# RA register map
Vendor: Renesas; Series: All Chips; File version: x.xx
Registers are 32-bit, read-write, reset 0x0 unless marked. A register's access mark holds for its fields unless they carry their own. Offsets are from the block's base; [hi:lo] are bit positions; lines under a group give offsets from that group; {n}, {i} and the like mark numbered series; 'fields as' and 'values as' point back to an identical list.

## R_ETHERC_EPTPC — Ethernet PTP Controller
Base 0x40065800
Same registers: R_ETHERC_EPTPC1 0x40065C00
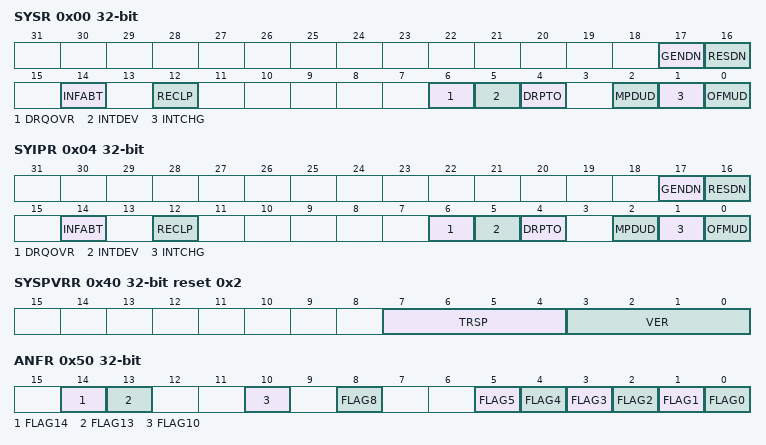
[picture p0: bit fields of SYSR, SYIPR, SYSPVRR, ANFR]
0x00 SYSR — SYNFP Status Register
  [17] GENDN write-1-clears read-modifies — Generation Stop Completion Detection Flag
    0=Stopping generation has not been completed; 1=Stopping generation has been completed
  [16] RESDN write-1-clears read-modifies — Response Stop Completion Detection Flag
    0=Stopping responses has not been completed; 1=Stopping responses has been completed
  [14] INFABT write-1-clears read-modifies — Control Information Abnormality Detection Flag
    0=No abnormality in control information; 1=Abnormality in control information
  [12] RECLP write-1-clears read-modifies — Loop Reception Detection Flag
    0=A received message has not returned through a loop; 1=A received message has returned through a loop
  [6] DRQOVR write-1-clears read-modifies — Delay_Req Reception FIFO Overflow Detection Flag
    0=The received Delay_Req has not caused the reception FIFO to overflow; 1=The received Delay_Req has caused the reception FIFO to overflow
  [5] INTDEV write-1-clears read-modifies — Receive logMessageInterval Value Out-of-Range Flag
    0=The received logMessageInterval value is within the range; 1=The received logMessageInterval value is out of the range
  [4] DRPTO write-1-clears read-modifies — Delay_Resp/Pdelay_Resp Reception Timeout Detection Flag
    0=A Delay_Resp/Pdelay_Resp timeout has not occurred; 1=A Delay_Resp/Pdelay_Resp timeout has occurred
  [2] MPDUD write-1-clears read-modifies — meanPathDelay Value Update Flag
    0=The meanPathDelay value has not been updated; 1=The meanPathDelay value has been updated
  [1] INTCHG write-1-clears read-modifies — Receive logMessageInterval Value Change Detection Flag
    0=No change in the received logMessageInterval value; 1=A change in the received logMessageInterval value
  [0] OFMUD write-1-clears read-modifies — offsetFromMaster Value Update Flag
    0=The offsetFromMaster value has not been updated; 1=The offsetFromMaster value has been updated
0x04 SYIPR — SYNFP Status Notification Permission Register
  [17] GENDN — SYSR.GENDN Status Notification Permission
    0=Prohibits notification of the state of SYSR.GENDN; 1=Permits notification of the state of SYSR.GENDN
  [16] RESDN — SYSR.RESDN Status Notification Permission
    0=Prohibits notification of the state of SYSR.RESDN; 1=Permits notification of the state of SYSR.RESDN
  [14] INFABT — SYSR.INFABT Status Notification Permission
    0=Prohibits notification of the state of SYSR.INFABT; 1=Permits notification of the state of SYSR.INFABT
  [12] RECLP — SYSR.RECLP Status Notification Permission
    0=Prohibits notification of the state of SYSR.RECLP; 1=Permits notification of the state of SYSR.RECLP
  [6] DRQOVR — SYSR.DRQOVR Status Notification Permission
    0=Prohibits notification of the state of SYSR.DRQOVR; 1=Permits notification of the state of SYSR.DRQOVR
  [5] INTDEV — SYSR.INTDEV Status Notification Permission
    0=Prohibits notification of the state of SYSR.INTDEV; 1=Permits notification of the state of SYSR.INTDEV
  [4] DRPTO — SYSR.DRPTO Status Notification Permission
    0=Prohibits notification of the state of SYSR.DRPTO; 1=Permits notification of the state of SYSR.DRPTO
  [2] MPDUD — SYSR.MPDUD Status Notification Permission
    0=Prohibits notification of the state of SYSR.MPDUD; 1=Permits notification of the state of SYSR.MPDUD
  [1] INTCHG — SYSR.INTCHG Status Notification Permission
    0=Prohibits notification of the state of SYSR.INTCHG; 1=Permits notification of the state of SYSR.INTCHG
  [0] OFMUD — SYSR.OFMUD Status Notification Permission
    0=Prohibits notification of the state of SYSR.OFMUD; 1=Permits notification of the state of SYSR.OFMUD
0x10 SYMACRU — SYNFP MAC Address Registers
  [23:0] SYMACRU — These bits hold the setting for the higher-order 24 bits of the local MAC address.
0x14 SYMACRL — SYNFP MAC Address Registers
  [23:0] SYMACRL — These bits hold the setting for the lower-order 24 bits of the local MAC address.
0x18 SYLLCCTLR reset 0x3 — SYNFP LLC-CTL Value Register
  [7:0] CTL — LLC-CTL FieldThese bits specify the value used for the control field in the LLC sublayer when generating IEEE802.3 frames.
0x1C SYIPADDRR — SYNFP Local IP Address Register
  [31:0] SYIPADDRR — These bits hold the setting for the local IP address.
0x40 SYSPVRR reset 0x2 — SYNFP Specification Version Setting Register
  [7:4] TRSP — transportSpecific Field ValueThese bits are used to set the transportSpecific field value of the PTP v2 header.When a message is received, this value is compared with the transportSpecific field of the received frame.In generating messages, the value is used for the transportSpecific field of the frame for transmission.Set these bits to 0000b (IEEE 1588).
  [3:0] VER — versionPTP Field ValueThese bits are used to set the versionPTP field value of the PTP v2 header.When a message is received, this value is compared with the versionPTP field of the received frame.In generating messages, the value is used for the versionPTP field of the frame for transmission.Set these bits to 0010b (PTP v2).
0x44 SYDOMR — SYNFP Domain Number Setting Register
  [7:0] DNUM — domainNumber Field Value SettingThese bits are used to set the domainNumber field value of the PTP v2 header.When a message is received, this value is compared with the domainNumber field of the received frame as a condition for PTP reception processing.In generating messages, the value is used for the domainNumber field of the frame for transmission.
0x50 ANFR — Announce Message Flag Field Setting Register
  [14] FLAG14 — PTP profile Specific 2
    0=PTP profile Specific 2 is set to FALSE; 1=PTP profile Specific 2 is set to TRUE
  [13] FLAG13 — PTP profile Specific 1
    0=PTP profile Specific 1 is set to FALSE; 1=PTP profile Specific 1 is set to TRUE
  [10] FLAG10 — unicastFlag
    0=unicastFlag is set to FALSE; 1=unicastFlag is set to TRUE
  [8] FLAG8 — alternateMasterFlag
    0=alternateMasterFlag is set to FALSE; 1=alternateMasterFlag is set to TRUE
  [5] FLAG5 — frequencyTraceableThis bit is used to set the logical value of the frequencyTraceable member of timePropertiesDS.
    0=frequencyTraceable is set to FALSE; 1=frequencyTraceable is set to TRUE
  [4] FLAG4 — timeTraceableThis bit is used to set the logical value of the timeTraceable member of timePropertiesDS.
    0=timeTraceable is set to FALSE; 1=timeTraceable is set to TRUE
  [3] FLAG3 — ptpTimescaleThis bit is used to set the logical value of the ptpTimescale member of timePropertiesDS.
    0=ptpTimescale is set to FALSE; 1=ptpTimescale is set to TRUE
  [2] FLAG2 — currentUtcOffsetValidThis bit is used to set the logical value of the currentUtcOffsetValid member of timePropertiesDS.
    0=currentUtcOffsetValid is set to FALSE; 1=currentUtcOffsetValid is set to TRUE
  [1] FLAG1 — leap59This bit is used to set the logical value of the leap59 member of timePropertiesDS.
    0=leap59 is set to FALSE; 1=leap59 is set to TRUE
  [0] FLAG0 — leap61This bit is used to set the logical value of the leap61 member of timePropertiesDS.
    0=leap61 is set to FALSE; 1=leap61 is set to TRUE
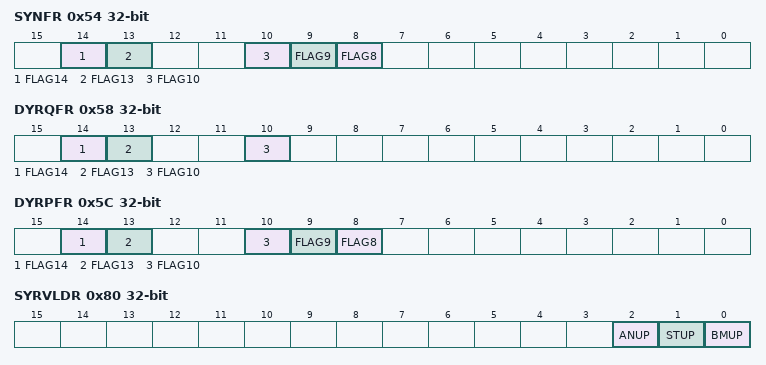
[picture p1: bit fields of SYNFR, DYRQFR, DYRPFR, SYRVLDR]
0x54 SYNFR — Sync Message Flag Field Setting Register
  [14] FLAG14 — PTP profile Specific 2
    values as ANFR.FLAG14
  [13] FLAG13 — PTP profile Specific 1
    values as ANFR.FLAG13
  [10] FLAG10 — unicastFlag
    0=unicastFlag is set to FALSE; 1=unicastFlag is set to TRUE
  [9] FLAG9 — twoStepFlag
    0=Set this bit to 0 (FALSE); 1=Setting prohibited
  [8] FLAG8 — alternateMasterFlag
    values as ANFR.FLAG8
0x58 DYRQFR — Delay_Req Message Flag Field Setting Register
  [14] FLAG14 — PTP profile Specific 2
    0=PTP profile Specific 2 is set to FALSE; 1=PTP profile Specific 2 is set to TRULE
  [13] FLAG13 — PTP profile Specific 1
    0=PTP profile Specific 1 is set to FALSE; 1=PTP profile Specific 1 is set to TRULE
  [10] FLAG10 — unicastFlag
    0=unicastFlag is set to FALSE; 1=unicastFlag is set to TRULE
0x5C DYRPFR — Delay_Resp Message Flag Field Setting Register
  [14] FLAG14 — PTP profile Specific 2
    values as ANFR.FLAG14
  [13] FLAG13 — PTP profile Specific 1
    values as ANFR.FLAG13
  [10] FLAG10 — unicastFlag
    0=unicastFlag is set to FALSE; 1=unicastFlag is set to TRUE
  [9] FLAG9 — woStepFlag
    0=Set this bit to 0 (FALSE); 1=Setting prohibited
  [8] FLAG8 — alternateMasterFlag
    values as ANFR.FLAG8
0x60 SYCIDRU — SYNFP Local Clock ID Registers
  [31:0] SYCIDRU — These bits hold the setting for the higher-order 32 bits of the clock-ID of your port.
0x64 SYCIDRL — SYNFP Local Clock ID Registers
  [31:0] SYCIDRL — These bits hold the setting for the lower-order 32 bits of the clock-ID of your port.
0x68 SYPNUMR — SYNFP Local Port Number Register
  [15:0] PNUM — Local Port Number SettingThese bits hold the setting for the port number of the local port.
0x80 SYRVLDR wo — SYNFP Register Value Load Directive Register
  [2] ANUP — Announce Message Generation Information Update
    0=no effect; 1=Setting this bit to 1 leads to simultaneous reflection in the Announce message generation block of the values of the registers required for the generation of Announce messages
  [1] STUP — State Update
    0=no effect; 1=Setting this bit to 1 leads to simultaneous reflection in the SYNFP module of the values of the registers related to the reception and transmission of PTP messages
  [0] BMUP — BMC Update
    0=no effect; 1=Setting this bit to 1 leads to simultaneous reflection in the SYNFP module of the values of the registers holding the MasterClock identifying information
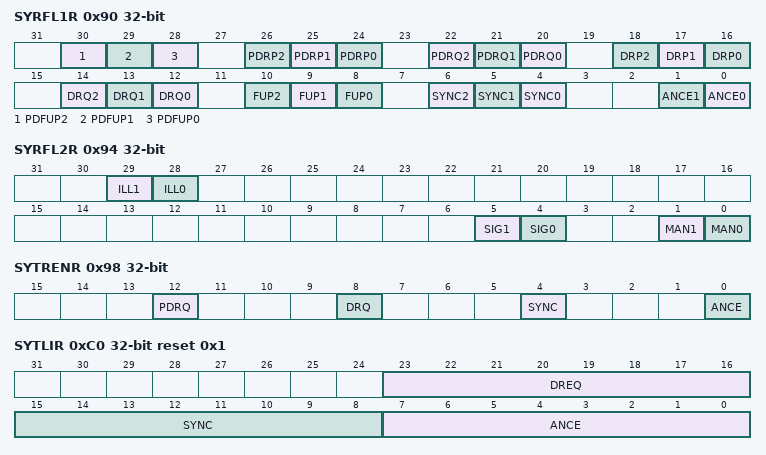
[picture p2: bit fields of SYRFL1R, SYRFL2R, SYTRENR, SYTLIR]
0x90 SYRFL1R — SYNFP Reception Filter Register 1
  [30] PDFUP2 — Pdelay_Resp_Follow_Up Message Processing
    0=The SYNFP does not process messages; 1=The SYNFP does not process messages
  [29] PDFUP1 — Pdelay_Resp_Follow_Up Message Processing
    0=The PRC-TC does not relay messages between ports 0 and 1; 1=The PRC-TC relays messages between ports 0 and 1
  [28] PDFUP0 — Pdelay_Resp_Follow_Up Message Processing
    0=Messages are not transferred to the PTPEDMAC; 1=Messages are transferred to the PTPEDMAC
  [26] PDRP2 — Pdelay_Resp Message Processing
    0=The SYNFP does not process messages; 1=The SYNFP processes messages
  [25] PDRP1 — Pdelay_Resp Message Processing
    values as PDFUP1
  [24] PDRP0 — Pdelay_Resp Message Processing
    values as PDFUP0
  [22] PDRQ2 — Pdelay_Req Message Processing
    values as PDRP2
  [21] PDRQ1 — Pdelay_Req Message Processing
    values as PDFUP1
  [20] PDRQ0 — Pdelay_Req Message Processing
    values as PDFUP0
  [18] DRP2 — Delay_Resp Message Processing
    values as PDRP2
  [17] DRP1 — Delay_Resp Message Processing
    values as PDFUP1
  [16] DRP0 — Delay_Resp Message Processing
    values as PDFUP0
  [14] DRQ2 — Delay_Req Message Processing
    values as PDRP2
  [13] DRQ1 — Delay_Req Message Processing
    values as PDFUP1
  [12] DRQ0 — Delay_Req Message Processing
    values as PDFUP0
  [10] FUP2 — Follow_Up Message Processing
    values as PDRP2
  [9] FUP1 — Follow_Up Message Processing
    values as PDFUP1
  [8] FUP0 — Follow_Up Message Processing
    values as PDFUP0
  [6] SYNC2 — Sync Message Processing
    values as PDRP2
  [5] SYNC1 — Sync Message Processing
    values as PDFUP1
  [4] SYNC0 — Sync Message Processing
    values as PDFUP0
  [1] ANCE1 — Announce Message Processing
    values as PDFUP1
  [0] ANCE0 — Announce Message Processing
    values as PDFUP0
0x94 SYRFL2R — SYNFP Reception Filter Register 2
  [29] ILL1 — Illegal Message Processing Setting
    values as SYRFL1R.PDFUP1
  [28] ILL0 — Illegal Message Processing Setting
    values as SYRFL1R.PDFUP0
  [5] SIG1 — Signaling Message Processing Setting
    values as SYRFL1R.PDFUP1
  [4] SIG0 — Signaling Message Processing Setting
    values as SYRFL1R.PDFUP0
  [1] MAN1 — Management Message Processing Setting
    values as SYRFL1R.PDFUP1
  [0] MAN0 — Management Message Processing Setting
    values as SYRFL1R.PDFUP0
0x98 SYTRENR — SYNFP Transmission Enable Register
  [12] PDRQ — Pdelay_Req Message Transmission Enable
    0=Pdelay_Req messages are not transmitted; 1=Pdelay_Req messages are transmitted
  [8] DRQ — Delay_Req Message Transmission Enable
    0=Delay_Req messages are not transmitted; 1=Delay_Req messages are transmitted
  [4] SYNC — Sync Message Transmission Enable
    0=Sync messages are not transmitted; 1=Sync messages are transmitted
  [0] ANCE — Announce Message Transmission Enable
    0=Announce messages are not transmitted; 1=Announce messages are transmitted
0xA0 MTCIDU — Master Clock ID Registers
  [31:0] MTCIDU — These bits hold the setting for the higher-order 32 bits of the clock-ID of the master clock.
0xA4 MTCIDL — Master Clock ID Registers
  [31:0] MTCIDL — These bits hold the setting for the lower-order 32 bits of the clock-ID of the master clock.
0xA8 MTPID — Master clock port number register
  [15:0] PNUM — Master Clock Port Number SettingThese bits hold the setting for the port number of the master clock.
0xC0 SYTLIR reset 0x1 — SYNFP Transmission Interval Setting Register
  [23:16] DREQ — Delay_Req Transmission Interval Average Value/ Pdelay_Req Transmission Interval SettingThe bits set the average interval for the transmission of Delay_Req messages and the interval for the transmission of Pdelay_Req messages.The setting is also placed in the logMessageInterval field of Delay_Resp messages.
  [15:8] SYNC — Sync Message Transmission Interval SettingThese bits set the interval for the transmission of Sync messages. The setting is also placed in the logMessageInterval field of transmitted Sync messages.
  [7:0] ANCE — Announce Message Transmission Interval SettingThese bits set the interval for the transmission of Announce messages.
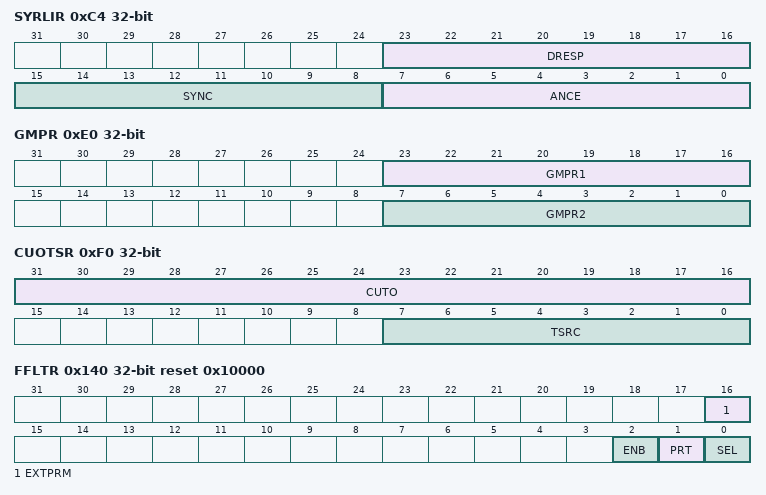
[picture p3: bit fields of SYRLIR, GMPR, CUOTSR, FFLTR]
0xC4 SYRLIR ro — SYNFP Received logMessageInterval Value Indication Register
  [23:16] DRESP — Delay_Resp Message logMessageInterval Field IndicationThese bits indicate the logMessageInterval field value of a received Delay_Resp message.
  [15:8] SYNC — Sync Message logMessageInterval Field IndicationThese bits indicate the logMessageInterval field value of a received Sync message.
  [7:0] ANCE — Announce Message logMessageInterval Field IndicationThese bits indicate the logMessageInterval field value of a received Announce message.
0xC8 OFMRU ro — offsetFromMaster Value Registers
  [31:0] OFMRU — These bits indicate the higher-order 32 bits of the calculated offsetFromMaster value.
0xCC OFMRL ro — offsetFromMaster Value Registers
  [31:0] OFMRL — These bits indicate the lower-order 32 bits of the calculated offsetFromMaster value.
0xD0 MPDRU ro — meanPathDelay Value Registers
  [31:0] MPDRU — These bits indicate the higher-order 32 bits of the calculated meanPathDelay value.
0xD4 MPDRL ro — meanPathDelay Value Registers
  [31:0] MPDRL — These bits indicate the lower-order 32 bits of the calculated meanPathDelay value.
0xE0 GMPR — grandmasterPriority Field Setting Register
  [23:16] GMPR1 — grandmasterPriority1 Field Value SettingThese bits are used to set the value of the grandmasterPriority1 fields of Announce messages.
  [7:0] GMPR2 — grandmasterPriority2 Field Value SettingThese bits are used to set the value of the grandmasterPriority2 fields of Announce messages.
0xE4 GMCQR — grandmasterClockQuality Field Setting Register
  [31:0] GMCQR — These bits are used to set the value of the grandmasterClockQuality fields of Announce messages. The correspondence between bits and the grandmasterClockQuality fields is as listed below.b31 to b24: clockClassb23 to b16: clockAccuracyb15 to b0: offsetScaledLogVariance
0xE8 GMIDRU — grandmasterIdentity Field Setting Registers
  [31:0] GMIDRU — These bits hold the setting for the higher-order 32 bits of the value of the grandmasterIdentity fields of Announce messages.
0xEC GMIDRL — grandmasterIdentity Field Setting Registers
  [31:0] GMIDRL — These bits hold the setting for the lower-order 32 bits of the value of the grandmasterIdentity fields of Announce messages.
0xF0 CUOTSR — currentUtcOffset/timeSource Field Setting Register
  [31:16] CUTO — currentUtcOffset Field SettingThese bits set the value of the currentUtcOffset fields of Announce messages.
  [7:0] TSRC — timeSource Field SettingThese bits set the value of the timeSource fields of Announce messages.
0xF4 SRR — stepsRemoved Field Setting Register
  [15:0] SRMV — stepsRemoved Field Value SettingThese bits set the value of the stepsRemoved fields of Announce messages.
0x100 PPMACRU reset 0x11B19 — PTP-primary Message Destination MAC Address Setting Registers
  [23:0] PPMACRU — These bits hold the setting for the higher-order 24 bits of the destination MAC address for PTP-primary messages.
0x104 PPMACRL — PTP-primary Message Destination MAC Address Setting Registers
  [23:0] PPMACRL — These bits hold the setting for the lower-order 24 bits of the destination MAC address for PTP-primary messages.
0x108 PDMACRU reset 0x180C2 — PTP-pdelay Message MAC Address Setting Registers
  [23:0] PDMACRU — These bits hold the setting for the higher-order 24 bits of the destination MAC address for PTP-pdelay messages.
0x10C PDMACRL reset 0xE — PTP-pdelay Message MAC Address Setting Registers
  [23:0] PDMACRL — These bits hold the setting for the lower-order 24 bits of the destination MAC address for PTP-pdelay messages.
0x110 PETYPER reset 0x88F7 — PTP Message EtherType Setting Register
  [15:0] TYPE — PTP Message EtherType Value SettingThese bits hold the setting for the EtherType field value for frames in the Ethernet II format.
0x120 PPIPR reset 0xE0000181 — PTP-primary Message Destination IP Address Setting Register
  [31:0] PPIPR — These bits hold the setting for the destination IP address for PTPprimary messages.
0x124 PDIPR reset 0xE000006B — PTP-pdelay Message Destination IP Address Setting Register
  [31:0] PDIPR — These bits hold the setting for the destination IP address for PTPpdelay messages.
0x128 PETOSR — PTP Event Message TOS Setting Register
  [7:0] EVTO — PTP Event Message TOS Field Value SettingThese bits hold the setting for the value of the TOS field within the IPv4 headers of PTP event messages.
0x12C PGTOSR — PTP general Message TOS Setting Register
  [7:0] GETO — PTP general Message TOS Field Value SettingThese bits hold the setting for the value of the TOS field within the IPv4 headers of PTP general messages.
0x130 PPTTLR reset 0x80 — PTP-primary Message TTL Setting Register
  [7:0] PRTL — PTP-primary Message TTL Field Value SettingThese bits hold the setting for the value of the TTL field within the IPv4 headers of PTP-primary messages.
0x134 PDTTLR reset 0x1 — PTP-pdelay Message TTL Setting Register
  [7:0] PDTL — PTP-pdelay Message TTL Field ValueThese bits hold the setting for the value of the TTL field within the IPv4 headers of PTP-pdelay messages.
0x138 PEUDPR reset 0x13F — PTP Event Message UDP Destination Port Number Setting Register
  [15:0] EVUPT — PTP Event Message Destination Port Number SettingThese bits hold the setting for the value of the destination port number field within the UDP headers of PTP event messages.
0x13C PGUDPR reset 0x140 — PTP general Message UDP Destination Port Number Setting Register
  [15:0] GEUPT — PTP general Message Destination Port NumberThese bits hold the setting for the value of the destination port number field within the UDP headers of PTP general messages.
0x140 FFLTR reset 0x10000 — Frame Reception Filter Setting Register
  [16] EXTPRM — Extended Promiscuous ModeSetting
    0=Normal operation (unicast frames addressed to the EPTPC are received, filtering of PTP frames is applied, multicast filtering is applied, and all broadcast frames are received); 1=Extended promiscuous mode (all frames are received)
  [2] ENB — Reception Filter EnableNOTE: The setting of these bits is only effective when EXTPRM=0.
    0=Filtering is disabled (all multicast frames are received); 1=See PRT and SEL bit
  [1] PRT — Frame Reception EnableNOTE: The setting of these bits is only effective when EXTPRM=0 and ENB=1.
    0=Do not receive multicast frames; 1=See SEL bit
  [0] SEL — Receive MAC Address SelectNOTE: The setting of these bits is only effective when EXTPRM=0, ENB=1and RPT=1.
    0=Only receive multicast frames matching the MAC address setting in FMAC0R(U/L); 1=Only receive multicast frames matching the MAC address setting in FMAC1R(U/L)
{0x160+8i} F[{i}] (i=0..1) group — Frame Reception Filter Setting Registers
  {0x0+8j} MACRU[{j}] (j=0..1) — Frame Reception Filter MAC Address Setting Registers
    [23:0] FMACRU — These bits hold the setting for the higher-order 24 bits of the destination MAC address for received multicast frames.
  {0x4+8j} MACRL[{j}] (j=0..1) — Frame Reception Filter MAC Address Setting Registers
    [23:0] FMACRL — These bits hold the setting for the lower-order 24 bits of the destination MAC address for received multicast frames.
0x1C0 DASYMRU — Asymmetric Delay Setting Registers
  [15:0] DASYMRU — These bits hold the setting for the higher-order 16 bits of the asymmetric delay value.
0x1C4 DASYMRL — Asymmetric Delay Setting Registers
  [31:0] DASYMRL — These bits hold the setting for the lower-order 32 bits of the asymmetric delay value.
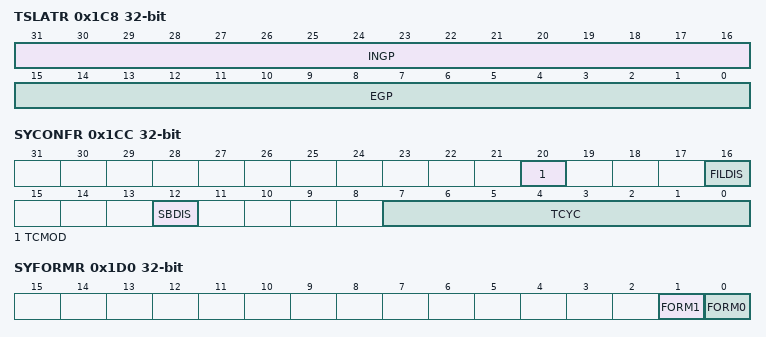
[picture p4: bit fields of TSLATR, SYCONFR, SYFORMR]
0x1C8 TSLATR — Timestamp Latency Setting Register
  [31:16] INGP — Output Port Timestamp Latency SettingThese bits hold the setting for the time stamp latency (ns) for the output ports.
  [15:0] EGP — Input Port Timestamp Latency SettingThese bits hold the setting for the time stamp latency (ns) for the input ports.
0x1CC SYCONFR — SYNFP Operation Setting Register
  [20] TCMOD — TC Mode Setting
    0=E2E TC; 1=P2P TC
  [16] FILDIS — Receive Message domainNumber Filter Disable
    0=Filtering conditions for the reception of PTP messages include comparison with the domainNumber field; 1=Filtering conditions for the reception of PTP messages do not include comparison with the domainNumber field
  [12] SBDIS — Sync Message Transmission Bandwidth Securing Disable
    0=Securing of the bandwidth for the transmission of SYNC messages is enabled (transfer by the EDMAC is given lower priority); 1=Securing of the bandwidth for the transmission of SYNC messages is disabled (transfer by the EDMAC is given higher priority)
  [7:0] TCYC — PTP Message Transmission Interval SettingThese bits are used to set the time from the completion of one transmission to the start of the next in cycles of the transmission clock. A value n in these bits means that a transmission interval of n cycles will be secured.No interval is secured if the setting is 00h.We recommend the setting 28h (40 cycles).
0x1D0 SYFORMR — SYNFP Frame Format Setting Register
  [1] FORM1 — Ethernet Frame Format Setting
    0=Set this bit to 0 (Ethernet II frame format); 1=Setting prohibited
  [0] FORM0 — Ethernet/UDP Encapsulation
    0=PTP directly over Ethernet; 1=PTP over UDP/IPv4
0x1D4 RSTOUTR — Response Message Reception Timeout Register
  [31:0] RSTOUTR — Response Message Reception Timeout Time SettingA response message not being received within n x 1024 (ns), where n is the setting, is judged to represent a timeout.
